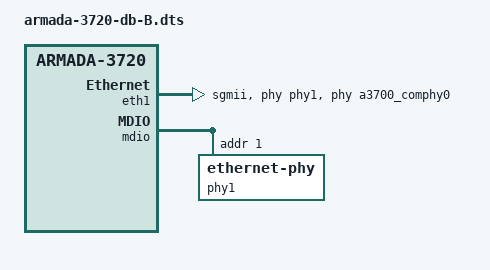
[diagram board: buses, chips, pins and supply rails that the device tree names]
// SPDX-License-Identifier: (GPL-2.0+ OR MIT)
/*
 * Device Tree file for Marvell Armada 3720 development board
 * This board file supports the B configuration of the board
 */

#include "armada-3720-db.dts"
/* This file enables eth1 to work on SERDES SGMII1 interface and
 * use SMI to do PHY polling, meanwhile eth0 still works on RGMII mode.
 */
/* Gigabit module on CON18(V2.0)/CON20(V1.4) */
&eth1 {
	status = "okay";
	/* Generic PHY, providing serdes lanes */
	phys = <&a3700_comphy0 1>;
	phy-mode = "sgmii";
	phy = <&phy1>;
};

&mdio {
	status = "okay";
	phy1: ethernet-phy@1 {
		reg = <1>;
	};
};

&usb3 {
	status = "disabled";
};
